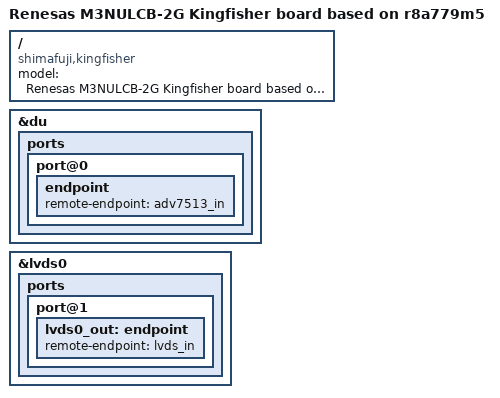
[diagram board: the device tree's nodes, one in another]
// SPDX-License-Identifier: GPL-2.0
/*
 * Device Tree Source for the M3NULCB-2G Kingfisher board
 *
 * Copyright (C) 2021 Renesas Electronics Corp.
 */

#include "r8a779m5-ulcb.dts"
#include "ulcb-kf.dtsi"

/ {
	model = "Renesas M3NULCB-2G Kingfisher board based on r8a779m5";
	compatible = "shimafuji,kingfisher", "renesas,m3nulcb",
		     "renesas,r8a779m5", "renesas,r8a77965";
};

&du {
	ports {
		port@0 {
			endpoint {
				remote-endpoint = <&adv7513_in>;
			};
		};
	};
};

&lvds0 {
	status = "okay";

	ports {
		port@1 {
			lvds0_out: endpoint {
				remote-endpoint = <&lvds_in>;
			};
		};
	};
};
